# STM32WBA62 register map
File version: 1.0
CPU: CM33 r0p1, little endian, MPU, FPU, 4 interrupt priority bits
Registers are 32-bit, read-write, reset 0x0 unless marked. A register's access mark holds for its fields unless they carry their own. Offsets are from the block's base; [hi:lo] are bit positions; {n}, {i} and the like mark numbered series.

## GPIOH — GPIOH address block description
Base 0x42021C00
Same registers: SEC_GPIOH 0x52021C00
0x00 GPIOH_MODER reset 0xC0 — GPIO port H mode register
  [7:6] MODE3 — Port H configuration I/O pin 3
    0=Input mode; 1=General purpose output mode; 2=Alternate function mode; 3=Analog mode (reset state)
0x04 GPIOH_OTYPER — GPIO port H output type register
  [3] OT3 — Port H configuration I/O pin 3
    0=Output push-pull (reset state); 1=Output open-drain
0x08 GPIOH_OSPEEDR — GPIO port H output speed register
  [7:6] OSPEED3 — Port H configuration I/O pin 3
    0=Low speed; 1=Medium speed; 2=High speed
0x0C GPIOH_PUPDR — GPIO port H pull-up/pull-down register
  [7:6] PUPD3 — Port H configuration I/O pin 3
    0=No pull-up, pull-down; 1=Pull-up; 2=Pull-down
0x10 GPIOH_IDR ro (reset mask 0xFFFF0000) — GPIO port H input data register
  [3] ID3 — Port H input data I/O pin 3
0x14 GPIOH_ODR — GPIO port H output data register
  [3] OD3 — Port H output data I/O pin 3
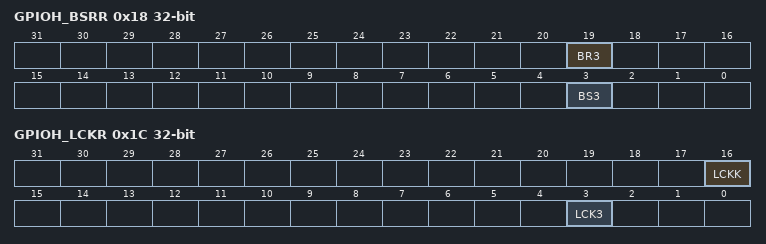
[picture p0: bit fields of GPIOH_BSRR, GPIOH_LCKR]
0x18 GPIOH_BSRR wo — GPIO port H bit set/reset register
  [19] BR3 — Port H reset I/O pin 3
    0=No action on the corresponding OD3 bit; 1=Resets the corresponding OD3 bit
  [3] BS3 — Port H set I/O pin 3
    0=No action on the corresponding OD3 bit; 1=Sets the corresponding OD3 bit
0x1C GPIOH_LCKR — GPIO port H configuration lock register
  [16] LCKK — Lock key
    0=Port configuration lock key not active; 1=Port configuration lock key active
  [3] LCK3 — Port H lock I/O pin 3
    0=Port configuration not locked; 1=Port configuration locked
0x20 GPIOH_AFRL — GPIO port H alternate function low register
  [15:12] AFSEL3 — Alternate function selection for port H I/O pin 3
    {v}=AF{v} (v=0..15)
0x28 GPIOH_BRR wo — GPIO port H bit reset register
  [3] BR3 — Port H reset I/O pin 3
    0=No action on the corresponding OD3 bit; 1=Reset the corresponding OD3 bit
0x30 GPIOH_SECCFGR reset 0x8 — GPIO port H secure configuration register
  [3] SEC3 — I/O pin of port H secure bit enable 3
    0=The I/O pin is nonsecure; 1=The I/O pin is secure

## GTZC_MPCBB1 — GTZC_MPCBB1 address block description
Base 0x40032C00
Same registers: GTZC_MPCBB2 0x40033000, SEC_GTZC_MPCBB1 0x50032C00, SEC_GTZC_MPCBB2 0x50033000
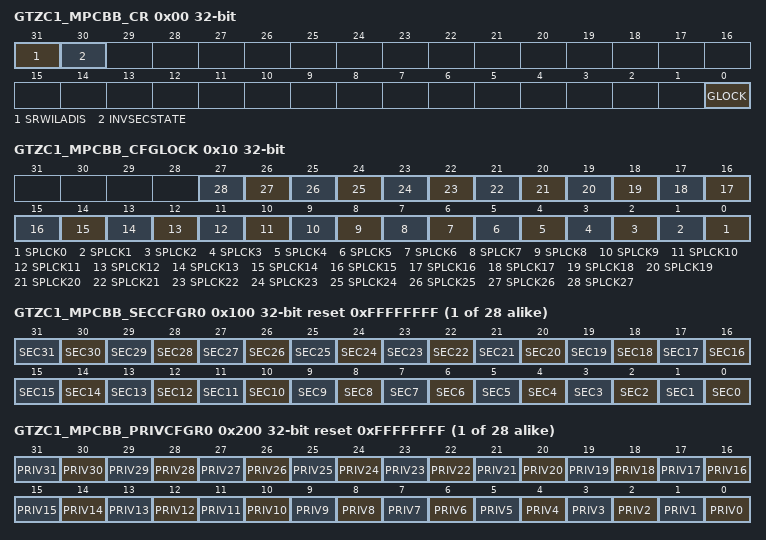
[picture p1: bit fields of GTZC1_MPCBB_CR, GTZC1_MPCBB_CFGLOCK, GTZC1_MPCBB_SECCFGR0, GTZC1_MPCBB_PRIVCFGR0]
0x00 GTZC1_MPCBB_CR (alternate view of GTZC1_TZSC_CR) — GTZC1 MPCBB control register
  [31] SRWILADIS — secure read/write illegal access disable
    0=enabled, secure read/write acces not allowed on Nonsecure SRAM block; 1=disabled, secure read/write access allowed on Nonsecure SRAM block
  [30] INVSECSTATE — SRAM clocks security state
    0=SRAM clock is secured if a secure area exists in the MPCBB; 1=SRAM clock is Nonsecure even if a secure area exists in the MPCBB, and secure even if no secure block is set in the MPCBB
  [0] GLOCK — Lock the control register of the MPCBB until next reset
    0=Control register not locked; 1=Control register locked
0x10 GTZC1_MPCBB_CFGLOCK (alternate view of GTZC1_TZSC_SECCFGR1) — GTZC1 MPCBB configuration lock register
  [all] fields
    0=GTZC1_MPCBB_SECCFGRn and GTZC1_MPCBB_PRIVCFGRn can be written; 1=Writes to GTZC1_MPCBB_SECCFGRn and GTZC1_MPCBB_PRIVCFGRn are ignored
  [n] SPLCK{n} (n=0..27) — Security/privilege configuration lock superblock
{0x100+4i} GTZC1_MPCBB_SECCFGR{i} reset 0xFFFFFFFF (i=0..27) — GTZC1 MPCBB security configuration for superblock {i} register
  [all] fields
    0=Nonsecure access only to block y, belonging to super-block n; 1=Secure access only to block y, belonging to super-block n
  [n] SEC{n} (n=0..31) — Security configuration for block y (y = 0 to 31) in super block n
{0x200+4i} GTZC1_MPCBB_PRIVCFGR{i} reset 0xFFFFFFFF (i=0..27) — GTZC1 MPCBB privileged configuration for superblock {i} register
  [all] fields
    0=Privileged and unprivileged access to block y, belonging to super-block n; 1=Only privileged access to block y, belonging to super-block n
  [n] PRIV{n} (n=0..31) — Privileged configuration for block y (y = 0 to 31), belonging to super-block n.

## Notices in the file
Copyright (c) 2025 STMicroelectronics.
SPDX-License-Identifier: Apache-2.0
Licensed under the Apache License, Version 2.0 (the "License");
you may not use this file except in compliance with the License.
You may obtain a copy of the License at
http://www.apache.org/licenses/LICENSE-2.0
Unless required by applicable law or agreed to in writing, software
distributed under the License is distributed on an "AS IS" BASIS,
WITHOUT WARRANTIES OR CONDITIONS OF ANY KIND, either express or implied.
See the License for the specific language governing permissions and
limitations under the License.
